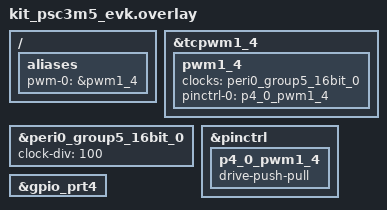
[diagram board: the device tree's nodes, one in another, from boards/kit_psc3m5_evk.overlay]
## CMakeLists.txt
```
# SPDX-License-Identifier: Apache-2.0

cmake_minimum_required(VERSION 3.28.0)

find_package(Zephyr REQUIRED HINTS $ENV{ZEPHYR_BASE})
project(pwm_event)

target_sources(app PRIVATE src/main.c)
```

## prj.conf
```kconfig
CONFIG_PWM=y
CONFIG_PWM_EVENT=y
```

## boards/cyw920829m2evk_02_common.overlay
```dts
/*
 * SPDX-FileCopyrightText: Copyright (c) 2026 Infineon Technologies AG,
 * SPDX-FileCopyrightText: or an affiliate of Infineon Technologies AG. All rights reserved.
 *
 * SPDX-License-Identifier: Apache-2.0
 */

/ {
	aliases {
		pwm-0 = &pwm0_1;
	};
};

&tcpwm0_1 {
	status = "okay";

	pwm0_1: pwm0_1 {
		clocks = <&peri0_group1_16bit_0>;
		pinctrl-0 = <&p3_6_pwm0_1>;
		pinctrl-names = "default";
		status = "okay";
	};
};

&peri0_group1_16bit_0 {
	clock-div = <100>;
	status = "okay";
};

&pinctrl {
	p3_6_pwm0_1: p3_6_pwm0_1 {
		drive-push-pull;
	};
};
```

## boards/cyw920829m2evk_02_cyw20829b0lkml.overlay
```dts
/*
 * Copyright (c) 2026 Infineon Technologies AG,
 * or an affiliate of Infineon Technologies AG.
 *
 * SPDX-License-Identifier: Apache-2.0
 */

#include "cyw920829m2evk_02_common.overlay"
```

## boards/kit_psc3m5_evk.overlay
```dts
/*
 * SPDX-FileCopyrightText: Copyright (c) 2026 Infineon Technologies AG,
 * SPDX-FileCopyrightText: or an affiliate of Infineon Technologies AG. All rights reserved.
 *
 * SPDX-License-Identifier: Apache-2.0
 */

/ {
	aliases {
		pwm-0 = &pwm1_4;
	};
};

&tcpwm1_4 {
	status = "okay";

	pwm1_4: pwm1_4 {
		clocks = <&peri0_group5_16bit_0>;
		pinctrl-0 = <&p4_0_pwm1_4>;
		pinctrl-names = "default";
		status = "okay";
	};
};

&peri0_group5_16bit_0 {
	clock-div = <100>;
	status = "okay";
};

&pinctrl {
	p4_0_pwm1_4: p4_0_pwm1_4 {
		drive-push-pull;
	};
};

&gpio_prt4 {
	status = "okay";
};
```

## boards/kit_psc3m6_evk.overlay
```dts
/*
 * SPDX-FileCopyrightText: Copyright (c) 2026 Infineon Technologies AG,
 * SPDX-FileCopyrightText: or an affiliate of Infineon Technologies AG. All rights reserved.
 *
 * SPDX-License-Identifier: Apache-2.0
 */

/ {
	aliases {
		pwm-0 = &pwm0_6;
	};
};
```

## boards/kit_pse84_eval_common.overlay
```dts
/*
 * SPDX-FileCopyrightText: Copyright (c) 2026 Infineon Technologies AG,
 * SPDX-FileCopyrightText: or an affiliate of Infineon Technologies AG. All rights reserved.
 *
 * SPDX-License-Identifier: Apache-2.0
 */

/ {
	aliases {
		pwm-0 = &pwm0_1;
	};
};

&tcpwm0_1 {
	status = "okay";

	pwm0_1: pwm0_1 {
		clocks = <&peri0_group1_16bit_1>;
		pinctrl-0 = <&p16_1_pwm0_1>;
		pinctrl-names = "default";
		status = "okay";
	};
};

&peri0_group1_16bit_1 {
	clock-div = <100>;
	status = "okay";
};

&pinctrl {
	p16_1_pwm0_1: p16_1_pwm0_1 {
		drive-push-pull;
	};
};
```

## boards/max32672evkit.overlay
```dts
/*
 * Copyright (c) 2026 Analog Devices, Inc.
 *
 * SPDX-License-Identifier: Apache-2.0
 */

&timer0 {
	clock-source = <ADI_MAX32_PRPH_CLK_SRC_PCLK>;
	prescaler = <1>;
	status = "okay";

	timer0_pwm: pwm {
		pinctrl-0 = <&tmr0c_oa_p0_17>;
		pinctrl-names = "default";
		status = "okay";
	};
};

/ {
	aliases {
		pwm-0 = &timer0_pwm;
	};
};
```

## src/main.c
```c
/*
 * Copyright (c) 2025 Basalte bv
 *
 * SPDX-License-Identifier: Apache-2.0
 */

#include <zephyr/drivers/pwm.h>
#include <zephyr/dt-bindings/pwm/pwm.h>
#include <zephyr/kernel.h>

#define N_PERIODS 5

#define PWM_CHANNEL   0
#define PWM_PERIOD_NS (1 * NSEC_PER_MSEC)

#if defined(CONFIG_PWM_MAX32)
#define PWM_FLAGS       PWM_POLARITY_INVERTED
#define PWM_FULL_LOW_NS PWM_PERIOD_NS
#else
#define PWM_FLAGS       PWM_POLARITY_NORMAL
#define PWM_FULL_LOW_NS 0
#endif

static struct pwm_event_callback callback;

static bool pwm_idle;
static uint8_t counter;

static void pwm_callback_handler(const struct device *dev, struct pwm_event_callback *cb,
				 uint32_t channel, pwm_events_t events)
{
	ARG_UNUSED(channel);
	ARG_UNUSED(events);
	int ret;

	if (++counter == N_PERIODS) {
		pwm_idle = !pwm_idle;
		counter = 0;

		ret = pwm_set(dev, PWM_CHANNEL, PWM_PERIOD_NS,
				  pwm_idle ? PWM_FULL_LOW_NS : PWM_PERIOD_NS / 2,
			      PWM_FLAGS);
		if (ret < 0) {
			printk("failed to set pwm (%d)\n", ret);
			(void)pwm_remove_event_callback(dev, cb);
			return;
		}
	}
}

int main(void)
{
	const struct device *const dev = DEVICE_DT_GET(DT_ALIAS(pwm_0));
	int ret;

	if (!device_is_ready(dev)) {
		printk("device is not ready\n");
		return 0;
	}

	ret = pwm_set(dev, PWM_CHANNEL, PWM_PERIOD_NS, PWM_PERIOD_NS / 2, PWM_FLAGS);
	if (ret < 0) {
		printk("failed to set idle (%d)\n", ret);
		return ret;
	}

	pwm_init_event_callback(&callback, pwm_callback_handler, PWM_CHANNEL,
				PWM_EVENT_TYPE_PERIOD);

	ret = pwm_add_event_callback(dev, &callback);
	if (ret < 0) {
		printk("failed to add event callback (%d)\n", ret);
		return ret;
	}

	return 0;
}
```
